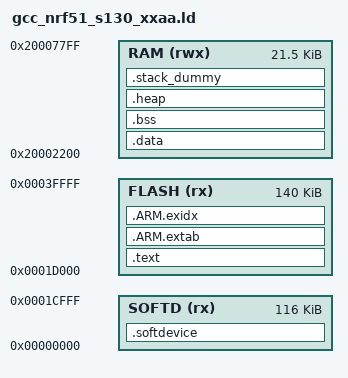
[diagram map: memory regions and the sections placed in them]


/* Linker script to place sections and symbol values. Should be used together
 * with other linker script that defines memory regions FLASH and RAM.
 * It references following symbols, which must be defined in code:
 *   Reset_Handler : Entry of reset handler
 *
 * It defines following symbols, which code can use without definition:
 *   __exidx_start
 *   __exidx_end
 *   __etext
 *   __data_start__
 *   __preinit_array_start
 *   __preinit_array_end
 *   __init_array_start
 *   __init_array_end
 *   __fini_array_start
 *   __fini_array_end
 *   __data_end__
 *   __bss_start__
 *   __bss_end__
 *   __end__
 *   end
 *   __HeapLimit
 *   __StackLimit
 *   __StackTop
 *   __stack
 */


OUTPUT_FORMAT ("elf32-littlearm", "elf32-bigarm", "elf32-littlearm")
ENTRY(Reset_Handler)
 /*
MEMORY
{
  SOFTD (rx) : ORIGIN = 0x00000000, LENGTH = 0x20000
  FLASH (rx) : ORIGIN = 0x00020000, LENGTH = 0x20000
  RAM (rwx) :  ORIGIN = 0x20002800, LENGTH = 0x1800
}
*/


MEMORY
{
  SOFTD (rx) : ORIGIN = 0x00000000, LENGTH = 0x1D000        /* [MANUEL] APP_CODE_BASE = SoftDevice + MBR = 112kB + 4kB = 116kB ( 116*2^10 = 118784 = 0x1D000 ) */
  FLASH (rx) : ORIGIN = 0x0001D000, LENGTH = 0x23000        /* [MANUEL] FLASH (256kB) - SofDevice = 256kB - 116kB = 256*2^10 - 116*2^10 = 143360 = 0x23000 */
  RAM (rwx) :  ORIGIN = 0x20002200, LENGTH = 0x5600         /* [MANUEL] RAM (32kB) - SoftDevice - MBR - CallStack = 32kB - 8.5kB - 0.0039kB - 2kB ~ 21.5kB ( 21.5*2^10 = 22016 = 0x5600 ) */
}


SECTIONS
{
    /* You can place the softdevice in this sector so that
     * it is included in the final image.
     */
    .softdevice :
    {
        KEEP(*(.softdevice*))
    }> SOFTD

    /* The normal application area of the device with SoftDevice
    */
	.text :
	{
		KEEP(*(.Vectors))
		*(.text*)

		KEEP(*(.init))
		KEEP(*(.fini))

		/* .ctors */
		*crtbegin.o(.ctors)
		*crtbegin?.o(.ctors)
		*(EXCLUDE_FILE(*crtend?.o *crtend.o) .ctors)
		*(SORT(.ctors.*))
		*(.ctors)

		/* .dtors */
 		*crtbegin.o(.dtors)
 		*crtbegin?.o(.dtors)
 		*(EXCLUDE_FILE(*crtend?.o *crtend.o) .dtors)
 		*(SORT(.dtors.*))
 		*(.dtors)

		*(.rodata*)

		*(.eh_frame*)
	} > FLASH


	.ARM.extab :
	{
		*(.ARM.extab* .gnu.linkonce.armextab.*)
	} > FLASH

	__exidx_start = .;
	.ARM.exidx :
	{
		*(.ARM.exidx* .gnu.linkonce.armexidx.*)
	} > FLASH
	__exidx_end = .;

	__etext = .;

	.data : AT (__etext)
	{
		__data_start__ = .;
		*(vtable)
		*(.data*)

		. = ALIGN(4);
		/* preinit data */
		PROVIDE_HIDDEN (__preinit_array_start = .);
		*(.preinit_array)
		PROVIDE_HIDDEN (__preinit_array_end = .);

		. = ALIGN(4);
		/* init data */
		PROVIDE_HIDDEN (__init_array_start = .);
		*(SORT(.init_array.*))
		*(.init_array)
		PROVIDE_HIDDEN (__init_array_end = .);


		. = ALIGN(4);
		/* finit data */
		PROVIDE_HIDDEN (__fini_array_start = .);
		*(SORT(.fini_array.*))
		*(.fini_array)
		PROVIDE_HIDDEN (__fini_array_end = .);

		*(.jcr)
		. = ALIGN(4);
		/* All data end */
		__data_end__ = .;

	} > RAM

	.bss :
	{
		. = ALIGN(4);
		__bss_start__ = .;
		*(.bss*)
		*(COMMON)
		. = ALIGN(4);
		__bss_end__ = .;
	} > RAM

	.heap (COPY):
	{
		__end__ = .;
		end = __end__;
		*(.heap*)
		__HeapLimit = .;
	} > RAM

	/* .stack_dummy section doesn't contains any symbols. It is only
	 * used for linker to calculate size of stack sections, and assign
	 * values to stack symbols later */
	.stack_dummy (COPY):
	{
		*(.stack*)
	} > RAM

	/* Set stack top to end of RAM, and stack limit move down by
	 * size of stack_dummy section */
	__StackTop = ORIGIN(RAM) + LENGTH(RAM);
	__StackLimit = __StackTop - SIZEOF(.stack_dummy);
	PROVIDE(__stack = __StackTop);

	/* Check if data + heap + stack exceeds RAM limit */
	ASSERT(__StackLimit >= __HeapLimit, "region RAM overflowed with stack")
}


